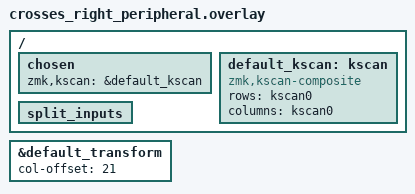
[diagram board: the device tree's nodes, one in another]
/ {
    chosen {
        zmk,kscan = &default_kscan;
    };

    default_kscan: kscan {
        compatible = "zmk,kscan-composite";
        rows = <&kscan0>;
        columns = <&kscan0>;
    };
};

&default_transform {
    col-offset = <21>;
};

/ {
    split_inputs {
        #address-cells = <1>;
        #size-cells = <0>;
    };
};
